# STM32H523 register map
File version: 1.3
CPU: CM33 r0p0, little endian, MPU, FPU, 4 interrupt priority bits
Registers are 32-bit, read-write, reset 0x0 unless marked. A register's access mark holds for its fields unless they carry their own. Offsets are from the block's base; [hi:lo] are bit positions; {n}, {i} and the like mark numbered series.

## USB — USB address block description
Base 0x40016000
Same registers: USB_S 0x50016000
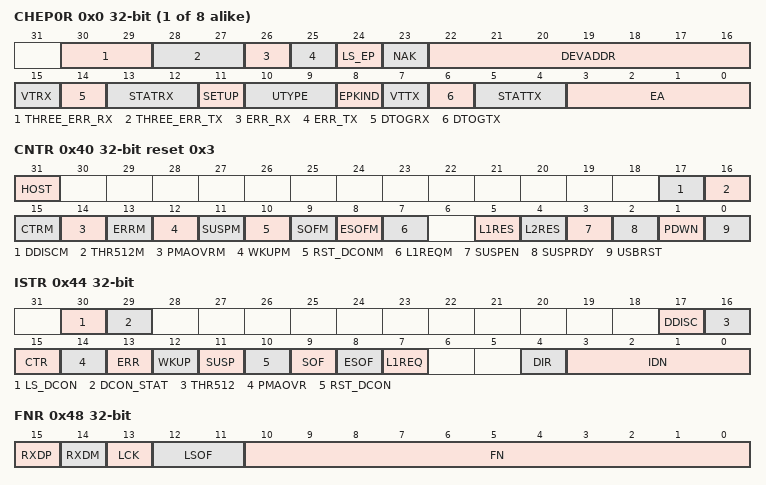
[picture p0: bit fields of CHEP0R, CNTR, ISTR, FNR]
{0x0+4i} CHEP{i}R (i=0..7) — USB endpoint/channel {i} register
  [30:29] THREE_ERR_RX — Three errors for an IN transaction
  [28:27] THREE_ERR_TX — Three errors for an OUT or SETUP transaction
  [26] ERR_RX write-0-clears — Received error for an IN transaction
    on write: 0=Clear flag
  [25] ERR_TX write-0-clears — Received error for an OUT/SETUP transaction
    on write: 0=Clear flag
  [24] LS_EP — Low speed endpoint host with HUB only
  [23] NAK write-0-clears — Host mode
    on write: 0=Clear flag
  [22:16] DEVADDR — Host mode
  [15] VTRX write-0-clears — USB valid transaction received
    on write: 0=Clear flag
  [14] DTOGRX write-1-toggles — Data Toggle, for reception transfers
    on read: 0=Expect0 (The next data packet received is expected to have the data toggle bit set to 0.); 1=Expect1 (The next data packet received is expected to have the data toggle bit set to 1.) | on write: 1=Toggle (Flip bit)
  [13:12] STATRX write-1-toggles — Status bits, for reception transfers
    on read: 0=Disabled (All reception requests addressed to this endpoint/channel are ignored.); 1=Stall (Device mode: the endpoint is stalled and all reception requests result in a STALL handshake. Host mode: this indicates that the device has STALLed the channel.); 2=Nak (Device mode: the endpoint is NAKed and all reception requests result in a NAK handshake. Host mode: this indicates that the device has NAKed the reception request.); 3=Valid (This endpoint/channel is enabled for reception.) | on write: 0=Keep (Do not change bits)
  [11] SETUP ro — Setup transaction completed
  [10:9] UTYPE — USB type of transaction
    0=Bulk endpoint; 1=Control endpoint; 2=Iso (Isochronous endpoint); 3=Interrupt endpoint
  [8] EPKIND — endpoint/channel kind
  [7] VTTX write-0-clears — Valid USB transaction transmitted
    on write: 0=Clear flag
  [6] DTOGTX write-1-toggles — Data toggle, for transmission transfers
    on read: 0=Send0 (The next data packet transmitted will have the data toggle bit set to 0.); 1=Send1 (The next data packet transmitted will have the data toggle bit set to 1.) | on write: 1=Toggle (Flip bit)
  [5:4] STATTX write-1-toggles — Status bits, for transmission transfers
    on read: 0=Disabled (All transmission requests addressed to this endpoint/channel are ignored.); 1=Stall (Device mode: the endpoint is stalled and all transmission requests result in a STALL handshake. Host mode: this indicates that the device has STALLed the channel.); 2=Nak (Device mode: the endpoint is NAKed and all transmission requests result in a NAK handshake. Host mode: this indicates that the device has NAKed the transmission request.); 3=Valid (This endpoint/channel is enabled for transmission.) | on write: 0=Keep (Do not change bits)
  [3:0] EA — endpoint/channel address
0x40 CNTR reset 0x3 — USB control register
  [31] HOST — HOST mode
  [17] DDISCM — Device disconnection mask
  [16] THR512M — 512 byte threshold interrupt mask
  [15] CTRM — Correct transfer interrupt mask
  [14] PMAOVRM — Packet memory area over / underrun interrupt mask
  [13] ERRM — Error interrupt mask
  [12] WKUPM — Wake-up interrupt mask
  [11] SUSPM — Suspend mode interrupt mask
  [10] RST_DCONM — USB reset request (Device mode) or device connect/disconnect (Host mode) interrupt mask
  [9] SOFM — Start of frame interrupt mask
  [8] ESOFM — Expected start of frame interrupt mask
  [7] L1REQM — LPM L1 state request interrupt mask
  [5] L1RES — L1 remote wake-up / resume driver
    0=NoEffect; 1=WakeupResume (Send 50us remote-wakeup signaling to host / Send L1 resume signaling to device)
  [4] L2RES — L2 remote wake-up / resume driver
  [3] SUSPEN — Suspend state enable
    0=NoEffect; 1=Suspend (Enter L1/L2 suspend)
  [2] SUSPRDY ro — Suspend state effective
  [1] PDWN — Power down
  [0] USBRST — USB Reset
    0=NoEffect; 1=Reset (USB core is under reset / USB reset driven)
0x44 ISTR — USB interrupt status register
  [30] LS_DCON ro — Low speed device connected
  [29] DCON_STAT ro — Device connection status
  [17] DDISC — Device connection
  [16] THR512 write-0-clears — 512 byte threshold interrupt
    on read: 0=NotReached (512 bytes threshold not reached); 1=Reached (512 bytes have been transmitted or received during isochronous transfers) | on write: 0=Clear flag
  [15] CTR ro — Completed transfer in host mode
    1=Completed (Endpoint has successfully completed a transaction)
  [14] PMAOVR write-0-clears — Packet memory area over / underrun
    on read: 0=NotOverrun (Overrun is not occurred); 1=Overrun (Microcontroller has not been able to respond in time to an USB memory request) | on write: 0=Clear flag
  [13] ERR write-0-clears — Error
    on read: 0=NotError (Errors are not occurred); 1=Error (One of No ANSwer, Cyclic Redundancy Check, Bit Stuffing or Framing format Violation error occurred) | on write: 0=Clear flag
  [12] WKUP write-0-clears — Wake-up
    on read: 0=NotWakeup; 1=Wakeup (Activity is detected that wakes up the USB peripheral) | on write: 0=Clear flag
  [11] SUSP write-0-clears — Suspend mode request
    on read: 0=NotSuspend; 1=Suspend (No traffic has been received for 3 ms, indicating a suspend mode request from the USB bus) | on write: 0=Clear flag
  [10] RST_DCON write-0-clears — USB reset request (Device mode) or device connect/disconnect (Host mode)
    on read: 0=NotReset; 1=Reset (Peripheral detects an active USB RESET signal at its inputs) | on write: 0=Clear flag
  [9] SOF write-0-clears — Start of frame
    on read: 0=NotStartOfFrame; 1=StartOfFrame (Beginning of a new USB frame and it is set when a SOF packet arrives through the USB bus) | on write: 0=Clear flag
  [8] ESOF write-0-clears — Expected start of frame
    on read: 0=NotExpectedStartOfFrame; 1=ExpectedStartOfFrame (An SOF packet is expected but not received) | on write: 0=Clear flag
  [7] L1REQ write-0-clears — LPM L1 state request
    on read: 0=NotL1State; 1=L1State (LPM command to enter the L1 state is successfully received and acknowledged) | on write: 0=Clear flag
  [4] DIR ro — Direction of transaction
    0=To (Data transmitted by the USB peripheral to the host PC); 1=From (Data received by the USB peripheral from the host PC)
  [3:0] IDN ro — Device Endpoint / host channel identification number
0x48 FNR ro (reset mask 0xFFFFF000) — USB frame number register
  [15] RXDP — Receive data + line status
  [14] RXDM — Receive data - line status
  [13] LCK — Locked
  [12:11] LSOF — Lost SOF
  [10:0] FN — Frame number
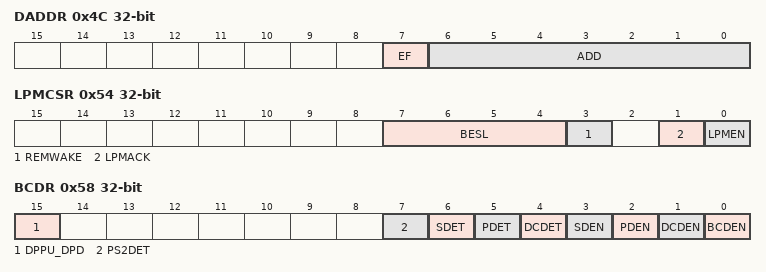
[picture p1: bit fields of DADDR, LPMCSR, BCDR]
0x4C DADDR — USB Device address
  [7] EF — Enable function
  [6:0] ADD — Device address
0x54 LPMCSR — LPM control and status register
  [7:4] BESL ro — BESL value
  [3] REMWAKE ro — bRemoteWake value
  [1] LPMACK — LPM token acknowledge enable
    0=Nyet (The valid LPM Token will be NYET / NYET answer); 1=Ack (The valid LPM Token will be ACK / ACK answer)
  [0] LPMEN — LPM support enable
0x58 BCDR — Battery charging detector
  [15] DPPU_DPD — DP pull-up / DPDM pull-down
  [7] PS2DET ro — DM pull-up detection status
  [6] SDET ro — Secondary detection (SD) status
  [5] PDET ro — Primary detection (PD) status
  [4] DCDET ro — Data contact detection (DCD) status
  [3] SDEN — Secondary detection (SD) mode enable
  [2] PDEN — Primary detection (PD) mode enable
  [1] DCDEN — Data contact detection (DCD) mode enable
  [0] BCDEN — Battery charging detector (BCD) enable
